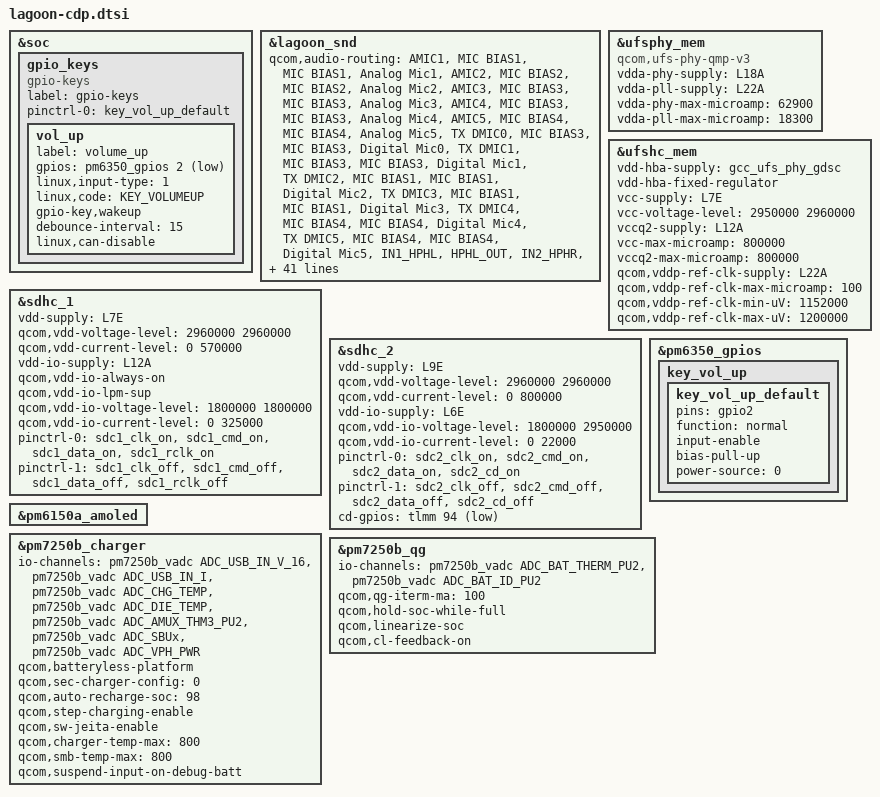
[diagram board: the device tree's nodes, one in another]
#include "lagoon-audio-overlay.dtsi"
#include <dt-bindings/gpio/gpio.h>

&soc {
};

&lagoon_snd {
	qcom,audio-routing =
		"AMIC1", "MIC BIAS1",
		"MIC BIAS1", "Analog Mic1",
		"AMIC2", "MIC BIAS2",
		"MIC BIAS2", "Analog Mic2",
		"AMIC3", "MIC BIAS3",
		"MIC BIAS3", "Analog Mic3",
		"AMIC4", "MIC BIAS3",
		"MIC BIAS3", "Analog Mic4",
		"AMIC5", "MIC BIAS4",
		"MIC BIAS4", "Analog Mic5",
		"TX DMIC0", "MIC BIAS3",
		"MIC BIAS3", "Digital Mic0",
		"TX DMIC1", "MIC BIAS3",
		"MIC BIAS3", "Digital Mic1",
		"TX DMIC2", "MIC BIAS1",
		"MIC BIAS1", "Digital Mic2",
		"TX DMIC3", "MIC BIAS1",
		"MIC BIAS1", "Digital Mic3",
		"TX DMIC4", "MIC BIAS4",
		"MIC BIAS4", "Digital Mic4",
		"TX DMIC5", "MIC BIAS4",
		"MIC BIAS4", "Digital Mic5",
		"IN1_HPHL", "HPHL_OUT",
		"IN2_HPHR", "HPHR_OUT",
		"IN3_AUX", "AUX_OUT",
		"TX SWR_ADC0", "ADC1_OUTPUT",
		"TX SWR_ADC1", "ADC2_OUTPUT",
		"TX SWR_ADC2", "ADC3_OUTPUT",
		"TX SWR_ADC3", "ADC4_OUTPUT",
		"TX SWR_DMIC0", "DMIC1_OUTPUT",
		"TX SWR_DMIC1", "DMIC2_OUTPUT",
		"TX SWR_DMIC2", "DMIC3_OUTPUT",
		"TX SWR_DMIC3", "DMIC4_OUTPUT",
		"TX SWR_DMIC4", "DMIC5_OUTPUT",
		"TX SWR_DMIC5", "DMIC6_OUTPUT",
		"TX SWR_DMIC6", "DMIC7_OUTPUT",
		"TX SWR_DMIC7", "DMIC8_OUTPUT",
		"WSA SRC0_INP", "SRC0",
		"WSA_TX DEC0_INP", "TX DEC0 MUX",
		"WSA_TX DEC1_INP", "TX DEC1 MUX",
		"RX_TX DEC0_INP", "TX DEC0 MUX",
		"RX_TX DEC1_INP", "TX DEC1 MUX",
		"RX_TX DEC2_INP", "TX DEC2 MUX",
		"RX_TX DEC3_INP", "TX DEC3 MUX",
		"SpkrLeft IN", "WSA_SPK1 OUT",
		"SpkrRight IN", "WSA_SPK2 OUT",
		"VA_AIF1 CAP", "VA_SWR_CLK",
		"VA_AIF2 CAP", "VA_SWR_CLK",
		"VA_AIF3 CAP", "VA_SWR_CLK",
		"VA MIC BIAS3", "Digital Mic0",
		"VA MIC BIAS3", "Digital Mic1",
		"VA MIC BIAS1", "Digital Mic2",
		"VA MIC BIAS1", "Digital Mic3",
		"VA MIC BIAS4", "Digital Mic4",
		"VA MIC BIAS4", "Digital Mic5",
		"VA DMIC0", "VA MIC BIAS3",
		"VA DMIC1", "VA MIC BIAS3",
		"VA DMIC2", "VA MIC BIAS1",
		"VA DMIC3", "VA MIC BIAS1",
		"VA DMIC4", "VA MIC BIAS4",
		"VA DMIC5", "VA MIC BIAS4",
		"VA SWR_ADC0", "VA_SWR_CLK",
		"VA SWR_ADC1", "VA_SWR_CLK",
		"VA SWR_ADC2", "VA_SWR_CLK",
		"VA SWR_ADC3", "VA_SWR_CLK",
		"VA SWR_MIC0", "VA_SWR_CLK",
		"VA SWR_MIC1", "VA_SWR_CLK",
		"VA SWR_MIC2", "VA_SWR_CLK",
		"VA SWR_MIC3", "VA_SWR_CLK",
		"VA SWR_MIC4", "VA_SWR_CLK",
		"VA SWR_MIC5", "VA_SWR_CLK",
		"VA SWR_MIC6", "VA_SWR_CLK",
		"VA SWR_MIC7", "VA_SWR_CLK",
		"VA SWR_ADC0", "ADC1_OUTPUT",
		"VA SWR_ADC1", "ADC2_OUTPUT",
		"VA SWR_ADC2", "ADC3_OUTPUT",
		"VA SWR_ADC3", "ADC4_OUTPUT",
		"VA SWR_MIC0", "DMIC1_OUTPUT",
		"VA SWR_MIC1", "DMIC2_OUTPUT",
		"VA SWR_MIC2", "DMIC3_OUTPUT",
		"VA SWR_MIC3", "DMIC4_OUTPUT",
		"VA SWR_MIC4", "DMIC5_OUTPUT",
		"VA SWR_MIC5", "DMIC6_OUTPUT",
		"VA SWR_MIC6", "DMIC7_OUTPUT",
		"VA SWR_MIC7", "DMIC8_OUTPUT";
};

&ufsphy_mem {
	compatible = "qcom,ufs-phy-qmp-v3";

	vdda-phy-supply = <&L18A>;
	vdda-pll-supply = <&L22A>;
	vdda-phy-max-microamp = <62900>;
	vdda-pll-max-microamp = <18300>;

	status = "ok";
};

&ufshc_mem {
	vdd-hba-supply = <&gcc_ufs_phy_gdsc>;
	vdd-hba-fixed-regulator;
	vcc-supply = <&L7E>;
	vcc-voltage-level = <2950000 2960000>;
	vccq2-supply = <&L12A>;
	vcc-max-microamp = <800000>;
	vccq2-max-microamp = <800000>;

	qcom,vddp-ref-clk-supply = <&L22A>;
	qcom,vddp-ref-clk-max-microamp = <100>;
	qcom,vddp-ref-clk-min-uV = <1152000>;
	qcom,vddp-ref-clk-max-uV = <1200000>;
	status = "ok";
};

&sdhc_1 {
	vdd-supply = <&L7E>;
	qcom,vdd-voltage-level = <2960000 2960000>;
	qcom,vdd-current-level = <0 570000>;

	vdd-io-supply = <&L12A>;
	qcom,vdd-io-always-on;
	qcom,vdd-io-lpm-sup;
	qcom,vdd-io-voltage-level = <1800000 1800000>;
	qcom,vdd-io-current-level = <0 325000>;

	pinctrl-names = "active", "sleep";
	pinctrl-0 = <&sdc1_clk_on &sdc1_cmd_on &sdc1_data_on
					&sdc1_rclk_on>;
	pinctrl-1 = <&sdc1_clk_off &sdc1_cmd_off &sdc1_data_off
					&sdc1_rclk_off>;

	status = "ok";
};

&sdhc_2 {
	vdd-supply = <&L9E>;
	qcom,vdd-voltage-level = <2960000 2960000>;
	qcom,vdd-current-level = <0 800000>;

	vdd-io-supply = <&L6E>;
	qcom,vdd-io-voltage-level = <1800000 2950000>;
	qcom,vdd-io-current-level = <0 22000>;

	pinctrl-names = "active", "sleep";
	pinctrl-0 = <&sdc2_clk_on  &sdc2_cmd_on &sdc2_data_on &sdc2_cd_on>;
	pinctrl-1 = <&sdc2_clk_off &sdc2_cmd_off &sdc2_data_off &sdc2_cd_off>;

	cd-gpios = <&tlmm 94 GPIO_ACTIVE_LOW>;

	status = "ok";
};

#include <dt-bindings/gpio/gpio.h>
#include <dt-bindings/input/linux-event-codes.h>
#include <dt-bindings/iio/qcom,spmi-vadc.h>

&soc {
	gpio_keys {
		compatible = "gpio-keys";
		label = "gpio-keys";

		pinctrl-names = "default";
		pinctrl-0 = <&key_vol_up_default>;

		vol_up {
			label = "volume_up";
			gpios = <&pm6350_gpios 2 GPIO_ACTIVE_LOW>;
			linux,input-type = <1>;
			linux,code = <KEY_VOLUMEUP>;
			gpio-key,wakeup;
			debounce-interval = <15>;
			linux,can-disable;
		};
	};
};

&pm6350_gpios {
	key_vol_up {
		key_vol_up_default: key_vol_up_default {
			pins = "gpio2";
			function = "normal";
			input-enable;
			bias-pull-up;
			power-source = <0>;
		};
	};
};

&pm6150a_amoled {
	status = "ok";
};

&pm7250b_charger {
	status = "ok";
	io-channels = <&pm7250b_vadc ADC_USB_IN_V_16>,
		      <&pm7250b_vadc ADC_USB_IN_I>,
		      <&pm7250b_vadc ADC_CHG_TEMP>,
		      <&pm7250b_vadc ADC_DIE_TEMP>,
		      <&pm7250b_vadc ADC_AMUX_THM3_PU2>,
		      <&pm7250b_vadc ADC_SBUx>,
		      <&pm7250b_vadc ADC_VPH_PWR>;
	io-channel-names = "usb_in_voltage",
			   "usb_in_current",
			   "chg_temp",
			   "die_temp",
			   "conn_temp",
			   "sbux_res",
			   "vph_voltage";
	qcom,batteryless-platform;
	qcom,sec-charger-config = <0>;
	qcom,auto-recharge-soc = <98>;
	qcom,step-charging-enable;
	qcom,sw-jeita-enable;
	qcom,charger-temp-max = <800>;
	qcom,smb-temp-max = <800>;
	qcom,suspend-input-on-debug-batt;
};

&pm7250b_qg {
	status = "ok";
	io-channels = <&pm7250b_vadc ADC_BAT_THERM_PU2>,
		      <&pm7250b_vadc ADC_BAT_ID_PU2>;
	io-channel-names = "batt-therm",
			   "batt-id";
	qcom,qg-iterm-ma = <100>;
	qcom,hold-soc-while-full;
	qcom,linearize-soc;
	qcom,cl-feedback-on;
};
